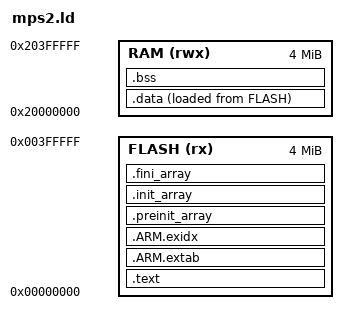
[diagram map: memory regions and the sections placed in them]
ENTRY(reset)
MEMORY
{
    FLASH (rx) : ORIGIN = 0x00000000, LENGTH = 4M
    RAM (rwx) : ORIGIN = 0x20000000, LENGTH = 4M
}
_stack_top = ORIGIN(RAM) + LENGTH(RAM);
SECTIONS
{
    .text : {
        KEEP(*(.isr_vector))
        *(.text*) *(.audio_ram_functions*) *(.audio_flash_functions*) *(.rodata*)
        KEEP(*(.init)) KEEP(*(.fini))
    } > FLASH
    .ARM.extab : { *(.ARM.extab*) } > FLASH
    .ARM.exidx : {
        __exidx_start = .;
        *(.ARM.exidx*)
        __exidx_end = .;
    } > FLASH
    .preinit_array : {
        __preinit_array_start = .;
        KEEP(*(.preinit_array*))
        __preinit_array_end = .;
    } > FLASH
    .init_array : {
        __init_array_start = .;
        KEEP(*(SORT(.init_array.*))) KEEP(*(.init_array))
        __init_array_end = .;
    } > FLASH
    .fini_array : {
        __fini_array_start = .;
        KEEP(*(SORT(.fini_array.*))) KEEP(*(.fini_array))
        __fini_array_end = .;
    } > FLASH
    .data : {
        . = ALIGN(4);
        _data_start = .;
        *(.data*)
        . = ALIGN(4);
        _data_end = .;
    } > RAM AT> FLASH
    _data_load = LOADADDR(.data);
    .bss (NOLOAD) : {
        . = ALIGN(4);
        _bss_start = .;
        *(.bss*) *(COMMON)
        . = ALIGN(4);
        _bss_end = .;
    } > RAM
    . = ALIGN(8);
    end = .;
    _end = .;
}
